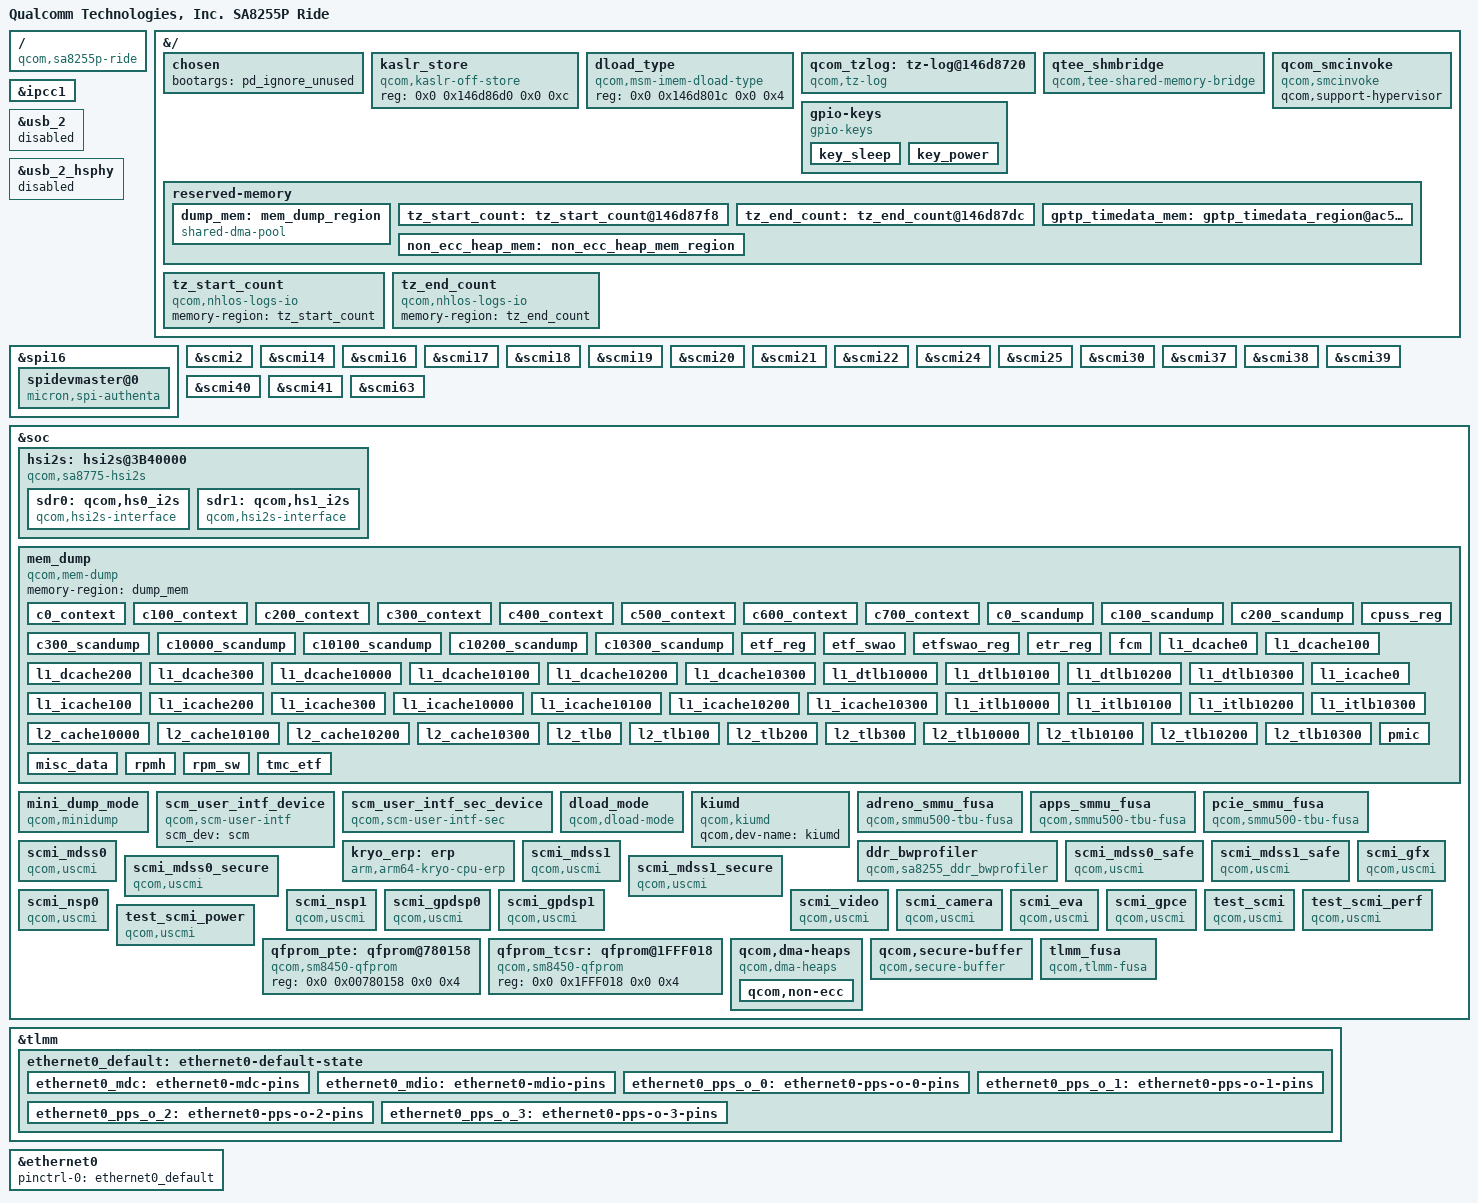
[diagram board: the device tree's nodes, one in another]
// SPDX-License-Identifier: BSD-3-Clause
/*
 * Copyright (c) Qualcomm Technologies, Inc. and/or its subsidiaries.
 */

#include <dt-bindings/interrupt-controller/irq.h>
#include <dt-bindings/interrupt-controller/arm-gic.h>
#include <dt-bindings/input/input.h>
#include <dt-bindings/gpio/gpio.h>
#include <dt-bindings/mailbox/qcom-ipcc.h>
#include <dt-bindings/mailbox/qcom-ipcc-sail.h>
#include <dt-bindings/dma-buf/heaps/qcom.h>
#include "sa8775p-pinctrl.dtsi"
#include "sa8775p-vfio.dtsi"

/ {
	model = "Qualcomm Technologies, Inc. SA8255P Ride";
	compatible = "qcom,sa8255p-ride","qcom,sa8255p";
};

&{/} {
	qcom,board-id = <0x10019 0>, <0x1010019 1>, <0x10025 0>, <0x1010025 1>;
	#address-cells = <2>;
	#size-cells = <2>;

	chosen {
		bootargs = "pd_ignore_unused";
	};

	kaslr_store {
		compatible = "qcom,kaslr-off-store";
		reg = <0x0 0x146d86d0 0x0 0xc>;
	};

	dload_type {
	       compatible = "qcom,msm-imem-dload-type";
	       reg = <0x0 0x146d801c 0x0 0x4>;
	};

	qcom_tzlog: tz-log@146d8720 {
		compatible = "qcom,tz-log";
		reg = <0x0 0x146d8720 0x0 0x3000>;
		qcom,hyplog-enabled;
		qcom,support-hypervisor;
		hyplog-address-offset = <0x410>;
		hyplog-size-offset = <0x414>;
	};

	qtee_shmbridge {
		compatible = "qcom,tee-shared-memory-bridge";
		qcom,support-hypervisor;
		memory-region = <&cma>;
	};

	qcom_smcinvoke {
		compatible = "qcom,smcinvoke";
		qcom,support-hypervisor;
	};

	gpio-keys {
		compatible = "gpio-keys";

		key_sleep {
			label = "sleep";
			linux,code = <KEY_SLEEP>;
			gpios = <&tlmm 6 GPIO_ACTIVE_HIGH>;
			linux,input-type = <1>;
			debounce-interval = <0>;
			wakeup-source;
		};

		key_power {
			label = "power";
			linux,code = <KEY_POWER>;
			gpios = <&tlmm 59 GPIO_ACTIVE_HIGH>;
			linux,input-type = <1>;
			debounce-interval = <0>;
			wakeup-source;
		};
	};

	reserved-memory {
		#address-cells = <2>;
		#size-cells = <2>;
		ranges;

		dump_mem: mem_dump_region {
			alloc-ranges = <0x0 0x00000000 0x0 0xffffffff>;
			compatible = "shared-dma-pool";
			reusable;
			size = <0 0x3000000>;
		};

		tz_start_count: tz_start_count@146d87f8 {
			reg = <0x0 0x146d87f8 0x0 0x8>;
			no-map;
		};

		tz_end_count: tz_end_count@146d87dc {
			reg = <0x0 0x146d87dc 0x0 0x8>;
			no-map;
		};

		gptp_timedata_mem: gptp_timedata_region@ac5fe000 {
			no-map;
			reg = <0x0 0xac5fe000 0x0 0x2000>;
		};

		non_ecc_heap_mem: non_ecc_heap_mem_region {
			reg = <0x9 0xC0000000 0x1 0x80000000>;
			no-map;
		};
	};

	tz_start_count {
		compatible = "qcom,nhlos-logs-io", "qcom,nhlos-logs";
		memory-region = <&tz_start_count>;
	};

	tz_end_count {
		compatible = "qcom,nhlos-logs-io", "qcom,nhlos-logs";
		memory-region = <&tz_end_count>;
	};
};

&ipcc1 {
	status = "okay";
};

&usb_2 {
	status = "disabled";
};

&usb_2_hsphy {
	status = "disabled";
};

&spi16 {
	spidevmaster@0 {
		/* FIXME: Replace below compatible once we have proper dt-bindings
		 * for the NXPs Mercury Audio DSP SAF4000EL/101(ES).
		 */
		compatible = "micron,spi-authenta";
		reg = <0>;
		spi-max-frequency = <10000000>;
		spi-cpha;
		status = "okay";
	};
};

&scmi2 {
	status = "okay";
};

&scmi14 {
	status = "okay";
};

&scmi16 {
	status = "okay";
};

&scmi17 {
	status = "okay";
};

&scmi18 {
	status = "okay";
};

&scmi19 {
	status = "okay";
};

&scmi20 {
	status = "okay";
};

&scmi21 {
	status = "okay";
};

&scmi22 {
	status = "okay";
};

&scmi24 {
	status = "okay";
};

&scmi25 {
	status = "okay";
};

&scmi30 {
	status = "okay";
};

&scmi37 {
	status = "okay";
};

&scmi38 {
	status = "okay";
};

&scmi39 {
	status = "okay";
};

&scmi40 {
	status = "okay";
};

&scmi41 {
	status = "okay";
};

&scmi63 {
	status = "okay";
};

&soc {
	hsi2s: hsi2s@3B40000 {
		compatible = "qcom,sa8775-hsi2s", "qcom,hsi2s";
		reg = <0x0 0x3B40000 0x0 0x29000>,
			<0x0 0x3942000 0x0 0x6000>;
		reg-names = "lpa_if", "lpass_core_cc_hs_if";
		interrupts = <GIC_SPI 719 IRQ_TYPE_LEVEL_HIGH>;
		number-of-rate-detectors = <2>;
		rate-detector-interfaces = <0 1>;
		number-of-interfaces = <2>;
		qcom,smmu-version = <2>;
		qcom,smmu-enabled;
		iommus = <&apps_smmu 0x303C 0x1>,
			<&apps_smmu 0x303A 0x4>,
			<&apps_smmu 0x303B 0x0>;
		qcom,iommu-dma-addr-pool = <0x0 0xFFFFFFFF>;
		dma-coherent;

		sdr0: qcom,hs0_i2s {
			compatible = "qcom,hsi2s-interface";
			minor-number = <0>;
			pinctrl-names = "default", "sleep";
			pinctrl-0 = <&hs0_i2s_sck_active
					&hs0_i2s_ws_active &hs0_i2s_data0_active
					&hs0_i2s_data1_active>;
			pinctrl-1 = <&hs0_i2s_sck_sleep
					&hs0_i2s_ws_sleep &hs0_i2s_data0_sleep
					&hs0_i2s_data1_sleep>;
			bit-clock-hz = <12288000>;
			data-buffer-ms = <10>;
			bit-depth = <32>;
			spkr-channel-count = <2>;
			mic-channel-count = <2>;
			pcm-rate = <2>;
			pcm-sync-src = <0>;
			aux-mode = <0>;
			rpcm-width = <1>;
			tpcm-width = <1>;
			enable-tdm = <1>;
			tdm-rate = <32>;
			tdm-rpcm-width = <16>;
			tdm-tpcm-width = <16>;
			tdm-sync-delay = <2>;
			tdm-inv-sync = <0>;
			pcm-lane-config = <1>;
		};

		sdr1: qcom,hs1_i2s {
			compatible = "qcom,hsi2s-interface";
			minor-number = <1>;
			pinctrl-names = "default", "sleep";
			pinctrl-0 = <&hs1_i2s_sck_active
					&hs1_i2s_ws_active &hs1_i2s_data0_active
					&hs1_i2s_data1_active>;
			pinctrl-1 = <&hs1_i2s_sck_sleep
					&hs1_i2s_ws_sleep &hs1_i2s_data0_sleep
					&hs1_i2s_data1_sleep>;
			bit-clock-hz = <12288000>;
			data-buffer-ms = <10>;
			bit-depth = <32>;
			spkr-channel-count = <2>;
			mic-channel-count = <2>;
			pcm-rate = <2>;
			pcm-sync-src = <0>;
			aux-mode = <0>;
			rpcm-width = <1>;
			tpcm-width = <1>;
			enable-tdm = <1>;
			tdm-rate = <32>;
			tdm-rpcm-width = <16>;
			tdm-tpcm-width = <16>;
			tdm-sync-delay = <2>;
			tdm-inv-sync = <0>;
			pcm-lane-config = <1>;
		};
	};

	mem_dump {
		compatible = "qcom,mem-dump";
		memory-region = <&dump_mem>;

		c0_context {
			qcom,dump-size = <0x800>;
			qcom,dump-id = <0x0>;
		};

		c100_context {
			qcom,dump-size = <0x800>;
			qcom,dump-id = <0x1>;
		};

		c200_context {
			qcom,dump-size = <0x800>;
			qcom,dump-id = <0x2>;
		};

		c300_context {
			qcom,dump-size = <0x800>;
			qcom,dump-id = <0x3>;
		};

		c400_context {
			qcom,dump-size = <0x800>;
			qcom,dump-id = <0x4>;
		};

		c500_context {
			qcom,dump-size = <0x800>;
			qcom,dump-id = <0x5>;
		};

		c600_context {
			qcom,dump-size = <0x800>;
			qcom,dump-id = <0x6>;
		};

		c700_context {
			qcom,dump-size = <0x800>;
			qcom,dump-id = <0x7>;
		};

		c0_scandump: c0_scandump {
			qcom,dump-size = <0x40000>;
			qcom,dump-id = <0x130>;
		};

		c100_scandump: c100_scandump {
			qcom,dump-size = <0x40000>;
			qcom,dump-id = <0x131>;
		};

		c200_scandump: c200_scandump {
			qcom,dump-size = <0x40000>;
			qcom,dump-id = <0x132>;
		};

		c300_scandump: c300_scandump {
			qcom,dump-size = <0x40000>;
			qcom,dump-id = <0x133>;
		};

		c10000_scandump: c10000_scandump {
			qcom,dump-size = <0x40000>;
			qcom,dump-id = <0x134>;
		};

		c10100_scandump: c10100_scandump {
			qcom,dump-size = <0x40000>;
			qcom,dump-id = <0x135>;
		};

		c10200_scandump: c10200_scandump {
			qcom,dump-size = <0x40000>;
			qcom,dump-id = <0x136>;
		};

		c10300_scandump: c10300_scandump {
			qcom,dump-size = <0x40000>;
			qcom,dump-id = <0x137>;
		};

		cpuss_reg: cpuss_reg {
			qcom,dump-size = <0x20000>;
			qcom,dump-id = <0xef>;
		};

		etf_reg {
			qcom,dump-size = <0x1000>;
			qcom,dump-id = <0x101>;
		};

		etf_swao {
			qcom,dump-size = <0x8400>;
			qcom,dump-id = <0xf1>;
		};

		etfswao_reg {
			qcom,dump-size = <0x1000>;
			qcom,dump-id = <0x102>;
		};

		etr_reg {
			qcom,dump-size = <0x1000>;
			qcom,dump-id = <0x100>;
		};

		fcm {
			qcom,dump-size = <0x8400>;
			qcom,dump-id = <0xee>;
		};

		l1_dcache0 {
			qcom,dump-size = <0x12100>;
			qcom,dump-id = <0x80>;
		};

		l1_dcache100 {
			qcom,dump-size = <0x12100>;
			qcom,dump-id = <0x81>;
		};

		l1_dcache200 {
			qcom,dump-size = <0x12100>;
			qcom,dump-id = <0x82>;
		};

		l1_dcache300 {
			qcom,dump-size = <0x12100>;
			qcom,dump-id = <0x83>;
		};

		l1_dcache10000 {
			qcom,dump-size = <0x12100>;
			qcom,dump-id = <0x84>;
		};

		l1_dcache10100 {
			qcom,dump-size = <0x12100>;
			qcom,dump-id = <0x85>;
		};

		l1_dcache10200 {
			qcom,dump-size = <0x12100>;
			qcom,dump-id = <0x86>;
		};

		l1_dcache10300 {
			qcom,dump-size = <0x12100>;
			qcom,dump-id = <0x87>;
		};

		l1_dtlb10000 {
			qcom,dump-size = <0x300>;
			qcom,dump-id = <0x44>;
		};

		l1_dtlb10100 {
			qcom,dump-size = <0x300>;
			qcom,dump-id = <0x45>;
		};

		l1_dtlb10200 {
			qcom,dump-size = <0x300>;
			qcom,dump-id = <0x46>;
		};

		l1_dtlb10300 {
			qcom,dump-size = <0x300>;
			qcom,dump-id = <0x47>;
		};

		l1_icache0 {
			qcom,dump-size = <0x26100>;
			qcom,dump-id = <0x60>;
		};

		l1_icache100 {
			qcom,dump-size = <0x26100>;
			qcom,dump-id = <0x61>;
		};

		l1_icache200 {
			qcom,dump-size = <0x26100>;
			qcom,dump-id = <0x62>;
		};

		l1_icache300 {
			qcom,dump-size = <0x26100>;
			qcom,dump-id = <0x63>;
		};

		l1_icache10000 {
			qcom,dump-size = <0x26100>;
			qcom,dump-id = <0x64>;
		};

		l1_icache10100 {
			qcom,dump-size = <0x26100>;
			qcom,dump-id = <0x65>;
		};

		l1_icache10200 {
			qcom,dump-size = <0x26100>;
			qcom,dump-id = <0x66>;
		};

		l1_icache10300 {
			qcom,dump-size = <0x26100>;
			qcom,dump-id = <0x67>;
		};

		l1_itlb10000 {
			qcom,dump-size = <0x300>;
			qcom,dump-id = <0x24>;
		};

		l1_itlb10100 {
			qcom,dump-size = <0x300>;
			qcom,dump-id = <0x25>;
		};

		l1_itlb10200 {
			qcom,dump-size = <0x300>;
			qcom,dump-id = <0x26>;
		};

		l1_itlb10300 {
			qcom,dump-size = <0x300>;
			qcom,dump-id = <0x27>;
		};

		l2_cache10000 {
			qcom,dump-size = <0x90100>;
			qcom,dump-id = <0xc4>;
		};

		l2_cache10100 {
			qcom,dump-size = <0x90100>;
			qcom,dump-id = <0xc5>;
		};

		l2_cache10200 {
			qcom,dump-size = <0x90100>;
			qcom,dump-id = <0xc6>;
		};

		l2_cache10300 {
			qcom,dump-size = <0x90100>;
			qcom,dump-id = <0xc7>;
		};

		l2_tlb0 {
			qcom,dump-size = <0x6100>;
			qcom,dump-id = <0x120>;
		};

		l2_tlb100 {
			qcom,dump-size = <0x6100>;
			qcom,dump-id = <0x121>;
		};

		l2_tlb200 {
			qcom,dump-size = <0x6100>;
			qcom,dump-id = <0x122>;
		};

		l2_tlb300 {
			qcom,dump-size = <0x6100>;
			qcom,dump-id = <0x123>;
		};

		l2_tlb10000 {
			qcom,dump-size = <0x6100>;
			qcom,dump-id = <0x124>;
		};

		l2_tlb10100 {
			qcom,dump-size = <0x6100>;
			qcom,dump-id = <0x125>;
		};

		l2_tlb10200 {
			qcom,dump-size = <0x6100>;
			qcom,dump-id = <0x126>;
		};

		l2_tlb10300 {
			qcom,dump-size = <0x6100>;
			qcom,dump-id = <0x127>;
		};

		misc_data {
			qcom,dump-size = <0x1000>;
			qcom,dump-id = <0xe8>;
		};

		pmic {
			qcom,dump-size = <0x80000>;
			qcom,dump-id = <0xe4>;
		};

		rpmh {
			qcom,dump-size = <0x2000000>;
			qcom,dump-id = <0xec>;
		};

		rpm_sw {
			qcom,dump-size = <0x28000>;
			qcom,dump-id = <0xea>;
		};

		tmc_etf {
			qcom,dump-size = <0x10000>;
			qcom,dump-id = <0xf0>;
		};

	};

	mini_dump_mode {
		compatible = "qcom,minidump";
		status = "ok";
	};

	scm_user_intf_device {
		compatible = "qcom,scm-user-intf";
		scm_dev = "scm";
		status = "ok";
	};

	scm_user_intf_sec_device {
		compatible = "qcom,scm-user-intf-sec";
		status = "ok";
	};

	dload_mode {
		compatible = "qcom,dload-mode";
		status = "ok";
	};

	kiumd {
		compatible = "qcom,kiumd";
		qcom,dev-name = "kiumd";
		status = "ok";
	};

	adreno_smmu_fusa {
		compatible = "qcom,smmu500-tbu-fusa";
		reg = <0x0 0x3da8000 0x0 0x20>,
		      <0x0 0x3dc8000 0x0 0x18000>;
		reg-name = "smmu_fusa_base", "client_fusa_base";
		qcom,client_offset = <0x8000>;
		interrupts = <GIC_SPI 769 IRQ_TYPE_LEVEL_HIGH>,
			     <GIC_SPI 818 IRQ_TYPE_LEVEL_HIGH>,
			     <GIC_SPI 819 IRQ_TYPE_LEVEL_HIGH>;
	};

	apps_smmu_fusa {
		compatible = "qcom,smmu500-tbu-fusa";
		reg = <0x0 0x15008000 0x0 0x20>,
		      <0x0 0x15180000 0x0 0x80000>;
		reg-name = "smmu_fusa_base", "client_fusa_base";
		qcom,client_offset = <0x8000>;
		interrupts = <GIC_SPI 779 IRQ_TYPE_LEVEL_HIGH>,
			     <GIC_SPI 453 IRQ_TYPE_LEVEL_HIGH>,
			     <GIC_SPI 458 IRQ_TYPE_LEVEL_HIGH>,
			     <GIC_SPI 717 IRQ_TYPE_LEVEL_HIGH>,
			     <GIC_SPI 718 IRQ_TYPE_LEVEL_HIGH>,
			     <GIC_SPI 662 IRQ_TYPE_LEVEL_HIGH>,
			     <GIC_SPI 667 IRQ_TYPE_LEVEL_HIGH>,
			     <GIC_SPI 671 IRQ_TYPE_LEVEL_HIGH>,
			     <GIC_SPI 716 IRQ_TYPE_LEVEL_HIGH>,
			     <GIC_SPI 762 IRQ_TYPE_LEVEL_HIGH>,
			     <GIC_SPI 767 IRQ_TYPE_LEVEL_HIGH>,
			     <GIC_SPI 829 IRQ_TYPE_LEVEL_HIGH>,
			     <GIC_SPI 821 IRQ_TYPE_LEVEL_HIGH>,
			     <GIC_SPI 466 IRQ_TYPE_LEVEL_HIGH>,
			     <GIC_SPI 461 IRQ_TYPE_LEVEL_HIGH>,
			     <GIC_SPI 464 IRQ_TYPE_LEVEL_HIGH>;
	};

	pcie_smmu_fusa {
		compatible = "qcom,smmu500-tbu-fusa";
		reg = <0x0 0x15208000 0x0 0x20>,
		      <0x0 0x152f0000 0x0 0x10000>;
		reg-name = "smmu_fusa_base", "client_fusa_base";
		qcom,client_offset = <0x8000>;
		interrupts = <GIC_SPI 652 IRQ_TYPE_LEVEL_HIGH>,
			     <GIC_SPI 645 IRQ_TYPE_LEVEL_HIGH>;
	};

	kryo_erp: erp {
	compatible = "arm,arm64-kryo-cpu-erp";
	interrupts = <GIC_PPI 0 IRQ_TYPE_LEVEL_LOW>,
			<GIC_SPI 36 IRQ_TYPE_LEVEL_HIGH>,
			<GIC_SPI 21 IRQ_TYPE_LEVEL_HIGH>;
	interrupt-names = "l1-l2-faultirq",
				"l3-c0-scu-faultirq",
				"l3-c1-scu-faultirq";
	};

	ddr_bwprofiler {
			compatible = "qcom,sa8255_ddr_bwprofiler";
			reg = <0x0 0x9200000 0x0 0x100000>,
			      <0x0 0x9300000 0x0 0x100000>,
			      <0x0 0x9400000 0x0 0x100000>,
			      <0x0 0x9500000 0x0 0x100000>,
			      <0x0 0x9600000 0x0 0x100000>,
			      <0x0 0x9700000 0x0 0x100000>,
			      <0x0 0x9152000 0x0 0x001000>,
			      <0x0 0x9153000 0x0 0x001000>,
			      <0x0 0x9154000 0x0 0x001000>,
			      <0x0 0x9155000 0x0 0x001000>,
			      <0x0 0x9156000 0x0 0x001000>,
			      <0x0 0x9157000 0x0 0x001000>,
			      <0x0 0x17A0000 0x0 0x040000>;
	};

	scmi_mdss0 {
		compatible = "qcom,uscmi";

		power-domains = <&scmi16_dvfs 0>;
		power-domain-names = "perf";

		qcom,dev-name = "scmi_mdss0";
	};

	scmi_mdss1 {
		compatible = "qcom,uscmi";

		power-domains = <&scmi17_dvfs 0>;
		power-domain-names = "perf";

		qcom,dev-name = "scmi_mdss1";
	};

	scmi_mdss0_safe {
		compatible = "qcom,uscmi";

		power-domains = <&scmi38_dvfs 0>;
		power-domain-names = "perf";

		qcom,dev-name = "scmi_mdss0_safe";
	};

	scmi_mdss1_safe {
		compatible = "qcom,uscmi";

		power-domains = <&scmi39_dvfs 0>;
		power-domain-names = "perf";

		qcom,dev-name = "scmi_mdss1_safe";
	};

	scmi_mdss0_secure {
		compatible = "qcom,uscmi";

		power-domains = <&scmi40_dvfs 0>;
		power-domain-names = "perf";

		qcom,dev-name = "scmi_mdss0_secure";
	};

	scmi_mdss1_secure {
		compatible = "qcom,uscmi";

		power-domains = <&scmi41_dvfs 0>;
		power-domain-names = "perf";

		qcom,dev-name = "scmi_mdss1_secure";
	};

	scmi_gfx {
		compatible = "qcom,uscmi";

		power-domains = <&scmi18_dvfs 0>;
		power-domain-names = "perf";

		qcom,dev-name = "scmi_gfx";
	};

	scmi_nsp0 {
		compatible = "qcom,uscmi";

		power-domains = <&scmi19_dvfs 0>;
		power-domain-names = "perf";

		qcom,dev-name = "scmi_nsp0";
	};

	scmi_nsp1 {
		compatible = "qcom,uscmi";

		power-domains = <&scmi19_dvfs 1>;
		power-domain-names = "perf";

		qcom,dev-name = "scmi_nsp1";
	};

	scmi_gpdsp0 {
		compatible = "qcom,uscmi";

		power-domains = <&scmi19_dvfs 2>;
		power-domain-names = "perf";

		qcom,dev-name = "scmi_gpdsp0";
	};

	scmi_gpdsp1 {
		compatible = "qcom,uscmi";

		power-domains = <&scmi19_dvfs 3>;
		power-domain-names = "perf";

		qcom,dev-name = "scmi_gpdsp1";
	};

	scmi_video {
		compatible = "qcom,uscmi";

		power-domains = <&scmi20_dvfs 0>, <&scmi20_dvfs 1>;
		power-domain-names = "perf_video_clk", "perf_video_bw";

		resets = <&scmi20_rst 0>;
		reset-names = "reset_video";

		qcom,dev-name = "scmi_video";
	};

	scmi_camera {
		compatible = "qcom,uscmi";

		power-domains = <&scmi21_dvfs 0>;
		power-domain-names = "perf_camera";

		qcom,dev-name = "scmi_camera";
	};

	scmi_eva {
		compatible = "qcom,uscmi";

		power-domains = <&scmi22_dvfs 0>, <&scmi22_dvfs 1>;
		power-domain-names = "perf_eva_clk", "perf_eva_bw";

		qcom,dev-name = "scmi_eva";
	};

	scmi_gpce {
		compatible = "qcom,uscmi";

		power-domains = <&scmi30_dvfs 0>;
		power-domain-names = "gpce_clock";

		qcom,dev-name = "scmi_gpce";
	};

	test_scmi {
		compatible = "qcom,uscmi";

		power-domains = <&scmi63_pd 2> , <&scmi63_dvfs 2>;
		power-domain-names = "power", "perf";

		resets = <&scmi63_rst 0>;
		reset-names = "core";

		qcom,dev-name = "test_scmi";
	};

	test_scmi_perf {
		compatible = "qcom,uscmi";

		power-domains = <&scmi63_dvfs 1>;
		power-domain-names = "perf";

		qcom,dev-name = "test_scmi_perf";
	};

	test_scmi_power {
		compatible = "qcom,uscmi";

		power-domains = <&scmi63_pd 1>;

		qcom,dev-name = "test_scmi_power";
	};

	qfprom_pte: qfprom@780158 {
		compatible = "qcom,sm8450-qfprom";
		reg = <0x0 0x00780158 0x0 0x4>;
		#address-cells = <1>;
		#size-cells = <1>;
	};

	qfprom_tcsr: qfprom@1FFF018 {
		compatible = "qcom,sm8450-qfprom";
		reg = <0x0 0x1FFF018 0x0 0x4>;
		#address-cells = <1>;
		#size-cells = <1>;
	};

	qcom,dma-heaps {
		compatible = "qcom,dma-heaps";
		status = "okay";

		qcom,non-ecc {
			qcom,dma-heap-name = "qcom,non-ecc";
			qcom,dma-heap-type = <HEAP_TYPE_CARVEOUT>;
			memory-region = <&non_ecc_heap_mem>;
		};
	};

	qcom,secure-buffer {
		compatible = "qcom,secure-buffer";
	};

	tlmm_fusa {
		compatible = "qcom,tlmm-fusa";
		interrupts = <GIC_SPI 445 IRQ_TYPE_EDGE_RISING>;
		reg = <0x0 0xf1b3000 0x0 0x2>,
		      <0x0 0xf1bb000 0x0 0x4>,
		      <0x0 0xf1bb008 0x0 0x4>;
		reg-names = "error_status", "ahb_hreset_status", "por_ares_status";
		qcom,por-ares-reset-bit = <2>;
	};
};

&tlmm {
	ethernet0_default: ethernet0-default-state {
		ethernet0_mdc: ethernet0-mdc-pins {
			pins = "gpio8";
			function = "emac0_mdc";
			drive-strength = <16>;
			bias-pull-up;
		};

		ethernet0_mdio: ethernet0-mdio-pins {
			pins = "gpio9";
			function = "emac0_mdio";
			drive-strength = <16>;
			bias-pull-up;
		};

		ethernet0_pps_o_0: ethernet0-pps-o-0-pins {
			pins = "gpio6";
			function = "emac0_ptp_pps";
			output-enable;
		};

		ethernet0_pps_o_1: ethernet0-pps-o-1-pins {
			pins = "gpio10";
			function = "emac0_ptp_pps";
			output-enable;
		};

		ethernet0_pps_o_2: ethernet0-pps-o-2-pins {
			pins = "gpio11";
			function = "emac0_ptp_pps";
			output-enable;
		};

		ethernet0_pps_o_3: ethernet0-pps-o-3-pins {
			pins = "gpio12";
			function = "emac0_ptp_pps";
			output-enable;
		};
	};
};

&ethernet0 {
	pinctrl-0 = <&ethernet0_default>;
	pinctrl-names = "default";
};
